# J7AEP_GPU_BXS464_WRAP0_GPU_SS_0_CORE_MMRS register map
Vendor: Texas Instruments
Peripheral module from a debugger description file (folder J721S2).
Registers are 64-bit, access per field, reset 0x0 unless marked. A register's access mark holds for its fields unless they carry their own. Offsets are as the file gives them; lines under a group give offsets from that group; [hi:lo] are bit positions; {n}, {i} and the like mark numbered series; 'fields as' and 'values as' point back to an identical list; <NAME> marks a mode.

## J7AEP_GPU_BXS464_WRAP0_GPU_SS_0_CORE_MMRS (part 1 of 5)
0x608 CORE_MMRS_RGX_CR_PDS_USC_COLLATOR — This register clear the internal resource tracking storage. It must be cleared after reste/power up. A write of '1' to this register clears the PDS Unified Clusters Resource Collator Contents. The PDS USC Resource Collator is a cross-DM controller, meaning this register must not be written during any active TA, 3D or Compute phase. This register must be written during the core initialisation sequence.
  [0] CLEAR wo — Clear PDS Unified Clusters Resource Collator
0x610 CORE_MMRS_RGX_CR_PDS_EXEC_BASE — Base Address in memory where the PDS programs are located
  [39:20] ADDR rw — 1TB addressable, 1 MB aligned base address for PDS programs
0x618 CORE_MMRS_RGX_CR_EVENT_PIXEL_PDS_CODE
  [31:4] ADDR rw — PDS Execution Address for pixel tasks [Positioned as a byte address, 128 bit granularity], 4 GB Range
0x620 CORE_MMRS_RGX_CR_EVENT_PIXEL_PDS_DATA
  fields as CORE_MMRS_RGX_CR_EVENT_PIXEL_PDS_CODE
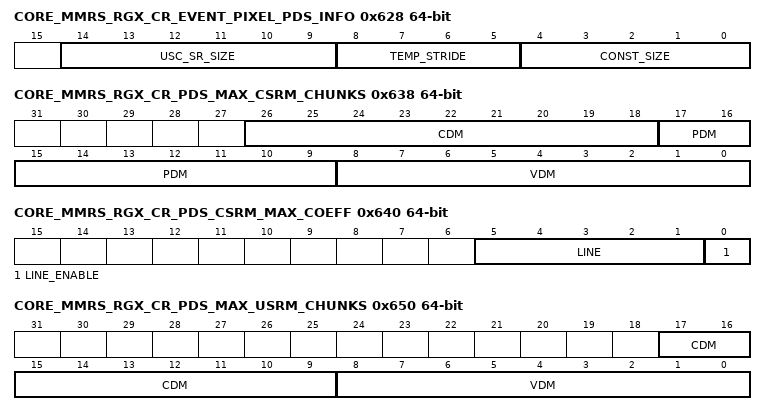
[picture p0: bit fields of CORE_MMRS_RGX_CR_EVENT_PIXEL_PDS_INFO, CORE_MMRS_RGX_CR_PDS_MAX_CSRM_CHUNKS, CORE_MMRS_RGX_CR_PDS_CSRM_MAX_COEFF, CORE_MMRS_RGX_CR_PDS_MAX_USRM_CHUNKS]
0x628 CORE_MMRS_RGX_CR_EVENT_PIXEL_PDS_INFO
  [14:9] USC_SR_SIZE rw — USC Shared Register Data Size in 4x128 bit words [0=0] for pixel event task, if zero pixel event task is skipped
  [8:5] TEMP_STRIDE rw — PDS Temp Size in 128 bit words [0=0] for pixel event tasks
  [4:0] CONST_SIZE rw — PDS Data Size in 128 bit words [0=0] for pixel event tasks, if zero pixel event task is skipped
0x630 CORE_MMRS_RGX_CR_PDS_CSRM — A write of '1' to this register clears the PDS Common Store Resource Manager Contents The PDS CSRM is a cross-DM controller, meaning this register must not be written during any active TA, 3D or Compute phase. This register must be written during the core initialisation sequence.
  [0] CLEAR wo — Clear PDS Common Store Resource Manager, a write to this register results in a one cycle pulse
0x638 CORE_MMRS_RGX_CR_PDS_MAX_CSRM_CHUNKS — Soft Limit Registers for Maximum Allocation Chunks in the Common Store on a Data Master basis. 1024 Allocation Regions exist in the Common Store. Each Allocation Region or Chunk represetns 4x128-bits of space in the Common Store. Setting a Field to 0x0 disables Max Chunk Allocation checking in the Common Store Resource Manager.
  [26:18] CDM rw — Max Number of Allocation Regions to Allocate to the Compute Data Master in Common Store
  [17:9] PDM rw — Max Number of Allocation Regions to Allocate to the Pixel Data Master in Common Store
  [8:0] VDM rw — Max Number of Allocation Regions to Allocate to the VDM Data Master in Common Store
0x640 CORE_MMRS_RGX_CR_PDS_CSRM_MAX_COEFF — The Common Store contains Coefficients and Shared Registers in a maximum of n Lines of 64 Allocation Chunks numbered 0-19, Allocated Dynamically. This Register sets a Soft Limit for the Maximum Line to Allocate for use as a Coefficient Line (0-0xn-1 are valid values)
  [5:1] LINE rw — Coefficients are allocated from Line 0 upwards, this is the maximum Line to use for Coefficients before wrapping
  [0] LINE_ENABLE rw — Enable Max Coefficient Line Limit
0x648 CORE_MMRS_RGX_CR_PDS_USRM — A write of '1' to this register clears the PDS Unified Store Resource Manager Contents. The PDS Unified Store Resource Manager only applies to the vertex and compute data masters. This register must be written during the core initialisation sequence.
  [0] CLEAR wo — Clear PDS Unified Store Resource Manager, a write to this register results in a one cycle pulse
0x650 CORE_MMRS_RGX_CR_PDS_MAX_USRM_CHUNKS — Soft Limit Registers for Maximum Allocation Chunks in the Unified Store on a Data Master basis. 400 Allocation Regions exist in the Unified Store. Each Allocation Region represents 4x128-bits of space in the Unified Store. Setting a Field to 0x0 disables Max Chunk Allocation checking in the Unified Store Resource Manager.
  [17:9] CDM rw — Max Number of Allocation Regions to Allocate to the Compute Data Master in Unified Store
  [8:0] VDM rw — Max Number of Allocation Regions to Allocate to the VDM Data Master in Unified Store
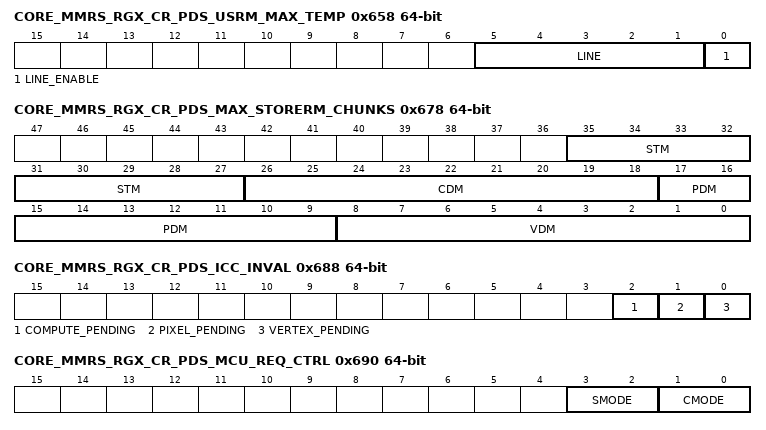
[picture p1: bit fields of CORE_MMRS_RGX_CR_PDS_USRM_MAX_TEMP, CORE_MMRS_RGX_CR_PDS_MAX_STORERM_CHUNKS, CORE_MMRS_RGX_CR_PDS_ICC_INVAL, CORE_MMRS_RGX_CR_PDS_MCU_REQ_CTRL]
0x658 CORE_MMRS_RGX_CR_PDS_USRM_MAX_TEMP — The Unified Store contains Temporaries and Attributes in n Lines of 16 Allocation Chunks numbered 0- n-1, Allocated Dynamically. This Register sets a Soft Limit for the Maximum Line to Allocate for use as a Temporaries Line (0-0xn-1 are valid values) Number of lines n can be calculated by taking the Unified Store Memory Bank Depth and dividing by 16. Hence for a US256 configuration, the USRM manages 16 lines, from 0-15. A smaller US208 configuration manages 13 lines, from 0-12.
  [5:1] LINE rw — Max Line for use as Temporaries
  [0] LINE_ENABLE rw — Enable Max Temporaries Line Limit
0x660 CORE_MMRS_RGX_CR_PDS_UVSRM — A write of '1' to this register clears the PDS Unified Vertex Store Resource Manager Contents The UVS Resource Manager only applies to the vertex data master. This register must be written during the core initialisation sequence.
  [0] CLEAR wo — Clear PDS Unified Vertex Store Resource Manager, a write to this register results in a one cycle pulse
0x670 CORE_MMRS_RGX_CR_PDS_STORERM — A write of '1' to this register clears the PDS Store Resource Manager Contents. The PDS Store Resource Manager is a cross-DM controller, meaning this register must not be written during any active TA, 3D or Compute phase. This register must be written during the core initialisation sequence.
  [0] CLEAR wo — Clear PDS Store Resource Manager, a write to this register results in a one cycle pulse
0x678 CORE_MMRS_RGX_CR_PDS_MAX_STORERM_CHUNKS — Soft Limit Registers for Maximum Allocation Chunks in the PDS Store on a Data Master basis. 488 Allocation Regions exist in the PDS Store. Each Allocation Chunk/Region represents 8x64-bits of space in the PDS Store. Setting a Field to 0x0 disables Max Chunk Allocation checking in the Common Store Resource Manager.
  [35:27] STM rw — Max Number of Allocation Regions to Allocate to the Stream Out Data Master in PDS Store
  [26:18] CDM rw — Max Number of Allocation Regions to Allocate to the Compute Data Master in PDS Store
  [17:9] PDM rw — Max Number of Allocation Regions to Allocate to the Pixel Data Master in PDS Store
  [8:0] VDM rw — Max Number of Allocation Regions to Allocate to the VDM Data Master in PDS Store
0x688 CORE_MMRS_RGX_CR_PDS_ICC_INVAL — A write of '1' any bit to this register clears the PDS Instruction Cache for the selected DM The PDS HW will clear the bits when the operations complete
  [2] COMPUTE_PENDING wo — PDS Instruction Cache Compute [DM 2] has been invalidated
  [1] PIXEL_PENDING wo — PDS Instruction Cache Pixel [DM 1] has been invalidated
  [0] VERTEX_PENDING wo — PDS Instruction Cache Vertex [DM 0] has been invalidated
0x690 CORE_MMRS_RGX_CR_PDS_MCU_REQ_CTRL — The PDS makes requests to the MCU to DMA to the PDS store and write data to memory. This register defines the various cache modes that apply to those requests.
  [3:2] SMODE rw — SLC cache policy to use for requests from the VDM/PDM/CDM/STM resource requestors inside the PDS
  [1:0] CMODE rw — Cache Mode to use for requests from the VDM/PDM/CDM/STM resource requestors inside the PDS
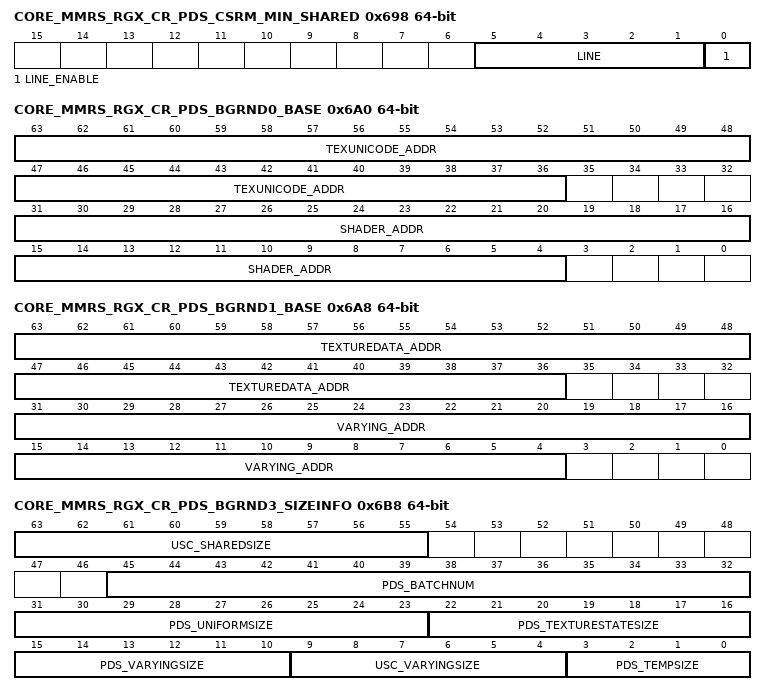
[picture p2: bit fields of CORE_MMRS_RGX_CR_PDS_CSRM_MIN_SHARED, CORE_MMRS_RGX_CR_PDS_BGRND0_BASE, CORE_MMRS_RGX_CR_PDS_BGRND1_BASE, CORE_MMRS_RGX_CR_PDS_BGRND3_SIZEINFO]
0x698 CORE_MMRS_RGX_CR_PDS_CSRM_MIN_SHARED — The Common Store contains Coefficients and Shared Registers in 14 Lines of 64 Allocation Chunks numbered 0-13, Allocated Dynamically. This Register sets a Soft Limit for the Minimum Line to Allocate for use as a Shared Line (0-0xD are valid values)
  [5:1] LINE rw — Shared are allocated from top line downwards, this is the minimum Line to use for Shared Registers before wrapping
  [0] LINE_ENABLE rw — Enable Min Shared Register Line Limit
0x6A0 CORE_MMRS_RGX_CR_PDS_BGRND0_BASE — PDS Background Setup Word 0
  [63:36] TEXUNICODE_ADDR rw — This is the PDS Code Address used for 2 programs. The Program which issues the DMAs [DOUTD etc. ] for uniform data and/or texture state.
  [31:4] SHADER_ADDR rw — The pixel shader base is the base address of the PDS Data Segment. The code segment is address is PDS_PIXEL_SHADERBASE + PDS_PIXELSHADERSIZE. The pixel shader program issues the DOUTU for the Fragment Shader only.
0x6A8 CORE_MMRS_RGX_CR_PDS_BGRND1_BASE — PDS Background Setup Word 1
  [63:36] TEXTUREDATA_ADDR rw — This points to the DMAs to load the Texture State [or contains the State with DOUTW commands]
  [31:4] VARYING_ADDR rw — This is the base address of the PDS Data Segment. The code segment is address is PDS_VARYINGBASE + PDS_VARYINGSIZE [PDS_BGRND_SIZEINFO1].
0x6B0 CORE_MMRS_RGX_CR_PDS_BGRND2_BASE — PDS Background Setup Word 2
  [31:4] UNIFORMDATA_ADDR rw — This points to the DMAs to load the Uniforms [or contains the Uniforms with DOUTW commands]
0x6B8 CORE_MMRS_RGX_CR_PDS_BGRND3_SIZEINFO — If any of the size fields are 0, then that program will not be run. PDS_BGRND_PIXELSHADERSIZE is always 2 128 Bit Words
  [63:55] USC_SHAREDSIZE rw — The common store allocation size for the shared registers [texture and uniform data commbined]
  [45:32] PDS_BATCHNUM rw — The batch ID to be associated with the background
  [31:23] PDS_UNIFORMSIZE rw — The size of the Uniform PDS Data Segment in 128 bit words
  [22:16] PDS_TEXTURESTATESIZE rw — The size of the Texture PDS Data Segment in 128 bit words
  [15:10] PDS_VARYINGSIZE rw — The size of the Varying/Coefficient PDS Data Segment in 128 bit words
  [9:4] USC_VARYINGSIZE rw — The size of the Varying/Coefficient USC Common Store Data in 4x128 bit words
  [3:0] PDS_TEMPSIZE rw — 0 = 0 128 bit words, 1 = 1 128 bit word, this applies to coefficient, uniform and varying state
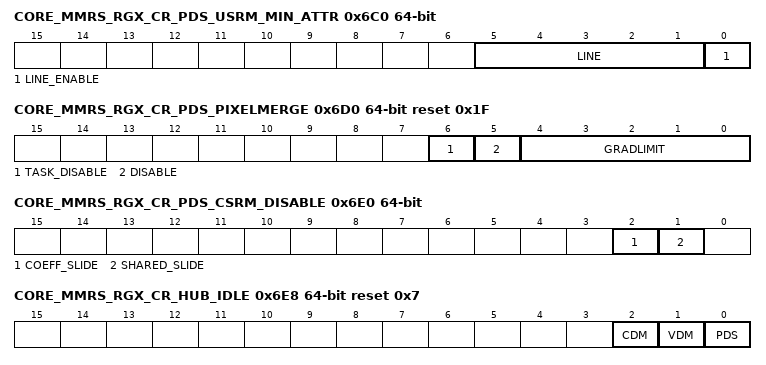
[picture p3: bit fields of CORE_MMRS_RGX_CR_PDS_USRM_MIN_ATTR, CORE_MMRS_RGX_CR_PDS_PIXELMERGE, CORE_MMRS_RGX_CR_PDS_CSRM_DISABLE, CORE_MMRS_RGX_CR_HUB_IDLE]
0x6C0 CORE_MMRS_RGX_CR_PDS_USRM_MIN_ATTR — The Unified Store contains Temporaries and Attributes in n Lines of 16 Allocation Chunks numbered 0 - n-1, Allocated Dynamically. This Register sets a Soft Limit for the Minimum Line to Allocate for use as an Attribute Line (0-0xn-1 are valid values) Number of lines n can be calculated by taking the Unified Store Memory Bank Depth and dividing by 16. Hence for a US256 configuration, the USRM manages 16 lines, from 0-15. A smaller US208 configuration manages 13 lines, from 0-12.
  [5:1] LINE rw — Min Line for use for Attributes
  [0] LINE_ENABLE rw — Enable Min Attributes Line Limit
0x6D0 CORE_MMRS_RGX_CR_PDS_PIXELMERGE reset 0x1F
  [6] TASK_DISABLE rw — Disable pixel merging within a whole pixel fragment task
  [5] DISABLE rw — Disable pixel merging within each 2x2 pixel block of a pixel fragment task
  [4:0] GRADLIMIT rw — Gradient difference limit for PDS PP pixel merging
0x6D8 CORE_MMRS_RGX_CR_PDS_CSRM_USC_DEBUG — When written a non zero value, this register assigns an extra degree of space to be allocated in the Common Store via the PDS CSRM for USC debugging on Shared Allocations. The SIZE field is Allocation Region Granular (i.e 512-bits, or 4x128-bit registers). This register must be set up before the PDS CSRM CLEAR operation.
  [4:0] SIZE rw — Amount of Space [in 512-bit Allocation Regions] to allocate to USC Debug Space on a Shared Allocation.
0x6E0 CORE_MMRS_RGX_CR_PDS_CSRM_DISABLE — When this register is set, the CSRM will be configured on PDS CSRM CLEAR to not reserve any space for Partitions (this is normally governed by the AA MODE and PIXEL OUTPUT CTRL WIDTH register settings), to maximise space in the CSRM for OCL operations. The Shared slide functionality which allows a Shared allocation which fails to slide the allocation window. The Coeff slide functionality allows a Coefficient allocation which fails to slide the allocation window.
  [2] COEFF_SLIDE rw — Disable Slide of Coeff Allocations on Failure
  [1] SHARED_SLIDE rw — Disable Slide of Shared Allocations on Failure
0x6E8 CORE_MMRS_RGX_CR_HUB_IDLE ro reset 0x7
  [2] CDM — CDM Module IDLE
  [1] VDM — VDM Module IDLE
  [0] PDS — PDS Module IDLE
0x6F0 CORE_MMRS_RGX_CR_HUB_PWR ro
  [31:0] NUM_PDS_INST — Number of PDS instructions
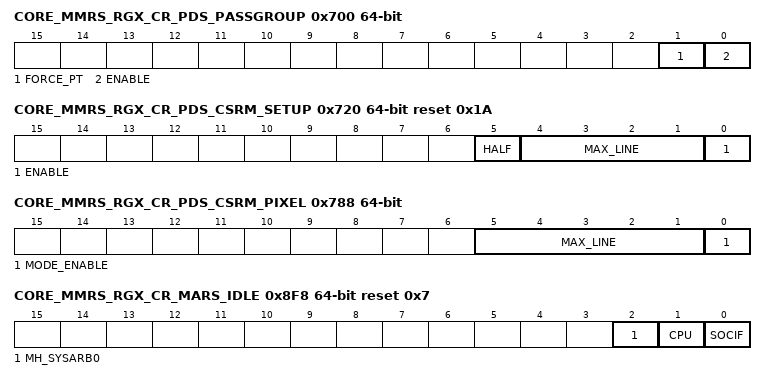
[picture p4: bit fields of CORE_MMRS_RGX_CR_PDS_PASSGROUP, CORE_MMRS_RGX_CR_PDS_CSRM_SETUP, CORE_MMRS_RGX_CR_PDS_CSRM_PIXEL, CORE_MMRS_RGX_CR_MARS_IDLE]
0x700 CORE_MMRS_RGX_CR_PDS_PASSGROUP
  [1] FORCE_PT rw — Force the use of Hard SDs between punchthrough or depth feedback type passes
  [0] ENABLE rw — Enable pass group optimisation within USC by replacing USC Hard SDs with USC Soft SDs for all pass groups in the PDS PP.
0x708 CORE_MMRS_RGX_CR_PDS_COMPUTE_THREAD_BARRIER
  [0] ENABLE rw — Enable thread barrier support in the PDS CDM_RR.
0x720 CORE_MMRS_RGX_CR_PDS_CSRM_SETUP reset 0x1A — If the ENABLE field is set, then when the PDS CSRM is Cleared via the PDS_CSRM_CLEAR register, the value set in the MAX_LINE vector is used to define the maximum Line in the CSRM which is allocatable to Shared Registers/Coefficients. The Space above is reserved for Pixel Partition Data. The CSRM manages space in the USC Common Store using a series of Lines of Allocation Regions. - Allocation Region = 4x128-bit Registers in the USC Common Store - CSRM Line = 64 Allocation Regions = 256x128-bit Registers in teh USC Common Store For CS1088 the maximum allocation size is 13.5 lines = 864 Alloc Regions = 3456 Registers Otherwise, the maximum allocation size is 12.5 lines = 800 Alloc Regions = 3200 Registers For these values the setup would be as follows: - CS1088 - Lines0-13 used, Line 13 is halffull, therefore MAX_LINE = 0xD, HALF = 1 - Non CS1088 - Lines0-12 used, Line 12 is halffull, therefore MAX_LINE = 0xC, HALF = 1
  [5] HALF rw — Top line is prefilled half full
  [4:1] MAX_LINE rw — [Lower 4 bits of] Maximum Line within the CSRM that can be allocated to Shared Registers/Coefficients
  [0] ENABLE rw — Enable use of this register to set the Maximum Line the CSRM can allocate on behalf of the USC Common Store
0x738 CORE_MMRS_RGX_CR_PDS_USRM_DISABLE — When this register is set, the USRM will be configured on PDS USRM CLEAR to disable the Temp/Attribute slide functionality which allows a Temporaries or Attributes allocation which fails to slide the allocation window. The CDM_TEMP_SLIDE bit when set will disable the Temporaries Failure Slide on Compute allocations that fail. The TEMP_FRAGMENTATION bit when set will disable Temporary allocations after window update until the oldest line in the window is empty.
  [0] TEMP_SLIDE rw — Disable Slide of Temp Allocations on Failure
0x788 CORE_MMRS_RGX_CR_PDS_CSRM_PIXEL — The Common Store contains Coefficients and Shared Registers in a maximum of n Lines of 64 Allocation Chunks numbered 0-31, Allocated Dynamically. This Register sets a Soft Limit for the Maximum Line of available Coefficient space, from line 0 upwards (set by PDS_CSRM_MAX_COEFF register) to Allocate for use ONLY by the Pixel Data Master (PDM) only (0-0xn-2 are valid values). Other lines above this limit may also be used for Pixels, but this area is reserved soley for Pixels when enabled.
  [5:1] MAX_LINE rw — Coefficients are allocated from Line 0 upwards, this is the maximum Line to reserve for ONLY PDM Coefficients. The Max line of this region is set in the PDS_CSRM_MAX_COEFF register
  [0] MODE_ENABLE rw — Enable PIXEL RESERVE MODE in the PDS CSRM
0x890 CORE_MMRS_RGX_CR_XPU_BROADCAST reset 0x1 — This register contains a bit for this, the primary XPU and for each secondary device connected to the primary. Bit 0 corresponds to the primary XPU and bits [1 .. GPU_COUNT-1] correspond to the secondary devices. This regsiter is initialised and masked using the GPU_COUNT input such that bits [8 . . GPU_COUNT] always read as '0'. By default, broadcast is enabled for all valid devices.
  [8:0] MASK rw — If bit N is set, forward broadcast XPU register writes to this device.
0x898 CORE_MMRS_RGX_CR_XPU_RW_ORDER reset 0x1
  [0] FORCE rw — 1 - Force reads and writes to complete in order with respect to each other on the XPU register AXI bus by stalling read requests if any writes are outstanding and vice versa. 0 - No ordering is enforced between reads and writes. Writes and reads complete in order with respect to themselves as dictated by AXI ID constraints.
0x8F0 CORE_MMRS_RGX_CR_SLAVE_EVENT ro — This register contains a bit for each slave connected to this, the master XPU. Valid bits are [XPU_MAX_SLAVES-1:0].
  [7:0] STATUS — If bit N is set, an interrupt from slave N is pending.
0x8F8 CORE_MMRS_RGX_CR_MARS_IDLE ro reset 0x7
  [2] MH_SYSARB0 — SYSARB0 Module IDLE
  [1] CPU — CPU Module IDLE
  [0] SOCIF — SOCIF Module IDLE
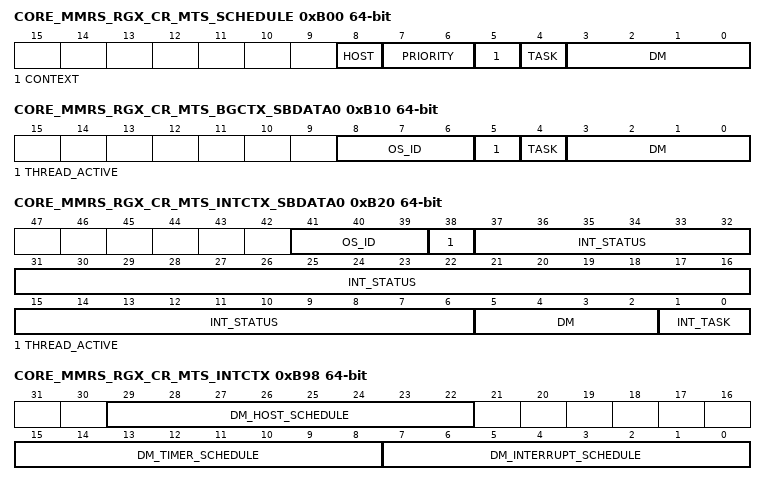
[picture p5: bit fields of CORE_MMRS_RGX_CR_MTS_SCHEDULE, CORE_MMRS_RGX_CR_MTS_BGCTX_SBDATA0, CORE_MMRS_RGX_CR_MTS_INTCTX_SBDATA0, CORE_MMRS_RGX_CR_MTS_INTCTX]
0xB00 CORE_MMRS_RGX_CR_MTS_SCHEDULE — This register allows firmware tasks to be scheduled on the META (Garten) core.
  [8] HOST wo — Host Interrupte kick
  [7:6] PRIORITY wo — DataMaster Priority
  [5] CONTEXT wo
  [4] TASK wo
  [3:0] DM wo — DataMaster Type
0xB08 CORE_MMRS_RGX_CR_MTS_PROC_COMPLETE — This register allows firmware tasks to signal process completion.
  [1] CONTEXT wo
0xB10 CORE_MMRS_RGX_CR_MTS_BGCTX_SBDATA0 ro — This register contains the sideband data for the process running on the background context of thread 0. Reads of this register will be redirected to the correct, thread specific register by hardware.
  [8:6] OS_ID — The OS_ID of the active thread
  [5] THREAD_ACTIVE — Indicates the thread is active
  [4] TASK
  [3:0] DM — DataMaster Type
0xB20 CORE_MMRS_RGX_CR_MTS_INTCTX_SBDATA0 ro — This register contains the sideband data for the process running on the interrupt context of thread 0. Reads of this register will be redirected to the correct, thread specific register by hardware.
  [41:39] OS_ID — The OS_ID of the active thread
  [38] THREAD_ACTIVE — Indicates the thread is active
  [37:6] INT_STATUS — Interrupt Status for 32 event bus lines
  [5:2] DM — DataMaster Type
  [1:0] INT_TASK — Kick Request for timer/BG-request/host
0xB30 CORE_MMRS_RGX_CR_MTS_BGCTX_THREAD0_DM_ASSOC — This register is the DataMaster assocation for the background context of thread 0. Bit <n> high represents DataMaster <n> being permitted to run on the background context of thread 0.
  [15:0] DM_ASSOC rw — DataMaster Association [Active High]
0xB40 CORE_MMRS_RGX_CR_MTS_INTCTX_THREAD0_DM_ASSOC — This register is the DataMaster assocation for the interrupt context of thread 0. Bit <n> high represents DataMaster <n> being permitted to run on the interrupt context of thread 0.
  [15:0] DM_ASSOC rw — DataMaster Association [Active High]
0xB50 CORE_MMRS_RGX_CR_MTS_GARTEN_WRAPPER_CONFIG reset 0x1 — This register contains the configuration options for the Garten wrapper.
  [0] IDLE_CTRL rw
{0xB58+8i} CORE_MMRS_RGX_CR_MTS_DM{i}_INTERRUPT_ENABLE (i=0..5) — Interrupt enable status register for DataMaster {i}
  [31:0] INT_ENABLE rw — Interrupt Enable
0xB88 CORE_MMRS_RGX_CR_MTS_EVENT_MASK — Mask interrupt events
  [31:0] MASK rw — DESCRIPTION
0xB90 CORE_MMRS_RGX_CR_MTS_EVENT_CLEAR — Clear internal interrupt registers
  [31:0] CLEAR wo — DESCRIPTION
0xB98 CORE_MMRS_RGX_CR_MTS_INTCTX ro — This register contains the sideband data for the MTS internal interrupt context registers
  [29:22] DM_HOST_SCHEDULE — A 1 bit counter per DM for host requests
  [15:8] DM_TIMER_SCHEDULE — A 1 bit counter per DM for timer requests
  [7:0] DM_INTERRUPT_SCHEDULE — A 1 bit counter per DM for interrupt requests
0xBA0 CORE_MMRS_RGX_CR_MTS_BGCTX ro — This register contains the sideband data for the MTS internal background context registers
  [7:0] DM_NONCOUNTED_SCHEDULE — A 1 bit counter per DM for non-counted background request
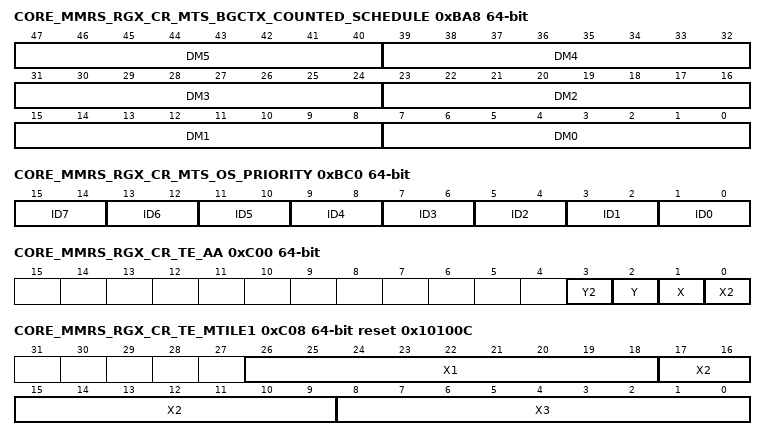
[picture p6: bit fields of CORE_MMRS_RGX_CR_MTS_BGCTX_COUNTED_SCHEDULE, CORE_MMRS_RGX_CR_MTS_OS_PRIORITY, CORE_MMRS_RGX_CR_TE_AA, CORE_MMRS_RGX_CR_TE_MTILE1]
0xBA8 CORE_MMRS_RGX_CR_MTS_BGCTX_COUNTED_SCHEDULE ro — This register contains the sideband data for the MTS internal counted background context counters
  [8n+7:8n] DM{n} (n=0..5) — A 8 bit counter for DM{n}
0xBB0 CORE_MMRS_RGX_CR_MTS_GPU_INT_STATUS ro — This register contains the sideband data for the MTS internal GPU interrupt status
  [31:0] STATUS — A 32 bit register for recored GPU events
0xBC0 CORE_MMRS_RGX_CR_MTS_OS_PRIORITY — Operating System Priority
  [2n+1:2n] ID{n} rw (n=0..7) — Scheduling priority for operating system {n}
0xBC8 CORE_MMRS_RGX_CR_MTS_SCHEDULE_ENABLE reset 0xFF — This register is an active-high mask. When the bit is 0, the MTS_SCHEDULE kick from the corresponding Guest OS is silently discarded. This allows the FW to mask out a Guest OS in order to prevent denial-of-service style attacks.
  [7:0] MASK rw
{0xBD8+0x10000*i} CORE_MMRS_RGX_CR_IRQ_OS{i}_EVENT_STATUS ro (i=0..7) — This register indicates the source of a per-OS host interrupt. This register is set by the firmware and cleared by the host.
  [0] SOURCE
0xBE0 CORE_MMRS_RGX_CR_HOST_IRQ — This register triggers a per-OS host interrupt. The hardware sets the corresponding RGX_CR_IRQ_OS<N>_EVENT_STATUS register.
  [2:0] OSID rw — Indicates the Guest OS for the interrupt
{0xBE8+0x10000*i} CORE_MMRS_RGX_CR_IRQ_OS{i}_EVENT_CLEAR (i=0..7) — This register clears a per-OS host interrupt.
  [0] SOURCE rw
0xBF8 CORE_MMRS_RGX_CR_META_BOOT
  [0] MODE rw — 0 = Don't boot, 1 = Boot
0xC00 CORE_MMRS_RGX_CR_TE_AA — This register controls the anti-aliasing mode of the Tiling Co-Processor, independent control is provided in both X & Y axis. This register needs to be set based on the ISP Samples Per Pixel a core supports. When ISP Samples Per Pixel = 1: 2xmsaa is achieved by enabling Y - TE does AA on Y plane only 4xmsaa is achieved by enabling Y and X - TE does AA on X and Y plane 8xmsaa not supported by XE cores When ISP Samples Per Pixel = 2: 2xmsaa is achieved by enabling X2 - does not affect TE 4xmsaa is achieved by enabling Y and X2 - TE does AA on Y plane only 8xmsaa is achieved by enabling Y, X and X2 - TE does AA on X and Y plane 8xmsaa not supported by XE cores When ISP Samples Per Pixel = 4: 2xmsaa is achieved by enabling X2 - does not affect TE 4xmsaa is achieved by enabling Y2 and X2 - TE does AA on Y plane only 8xmsaa not supported by XE cores
  [3] Y2 rw — Indicates 4xmsaa when X2 and Y2 are set to 1. This does not affect TE and is only used within TPW.
  [2] Y rw — Anti-Aliasing in Y Plane Enabled
  [1] X rw — Anti-Aliasing in X Plane Enabled
  [0] X2 rw — 2x Anti-Aliasing Enabled, affects PPP only
0xC08 CORE_MMRS_RGX_CR_TE_MTILE1 reset 0x10100C — MacroTile Boundaries X Plane
  [26:18] X1 rw — X1 MacroTile boundary, left tile X for second column of macrotiles [16MT mode] - 32 pixels across tile
  [17:9] X2 rw — X2 MacroTile boundary, left tile X for third[16MT] column of macrotiles - 32 pixels across tile
  [8:0] X3 rw — X3 MacroTile boundary, left tile X for fourth column of macrotiles [16MT] - 32 pixels across tile
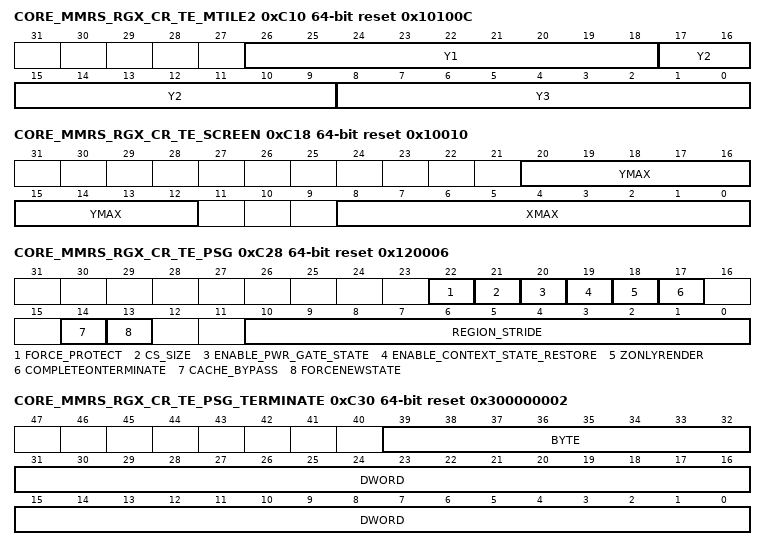
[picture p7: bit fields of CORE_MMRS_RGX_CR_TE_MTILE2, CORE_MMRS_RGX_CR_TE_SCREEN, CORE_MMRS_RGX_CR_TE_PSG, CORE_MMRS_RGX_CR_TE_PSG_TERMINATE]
0xC10 CORE_MMRS_RGX_CR_TE_MTILE2 reset 0x10100C — MacroTile Boundaries Y Plane.
  [26:18] Y1 rw — X1 MacroTile boundary, ltop tile Y for second column of macrotiles [16MT mode] - 32 pixels tile height
  [17:9] Y2 rw — X2 MacroTile boundary, top tile Y for third[16MT] column of macrotiles - 32 pixels tile height
  [8:0] Y3 rw — X3 MacroTile boundary, top tile Y for fourth column of macrotiles [16MT] - 32 pixels tile height
0xC18 CORE_MMRS_RGX_CR_TE_SCREEN reset 0x10010 — In order to perform the tiling operation and generate the display list the maximum screen size must be configured in terms of the number of tiles in X & Y axis.
  [20:12] YMAX rw — Maximum Y tile address visible on screen, 32 pixel tile height, 16Kx16K max screen size
  [8:0] XMAX rw — Maximum X tile address visible on screen, 32 pixel tile width, 16Kx16K max screen size
0xC20 CORE_MMRS_RGX_CR_TE_MTILE — In order to perform the tiling operation and generate the display list the maximum screen size must be configured in terms of the number of tiles in X & Y axis.
  [18:0] STRIDE rw — Number of tiles in a Macrotile. Stride = [XTile * YTiles], tiles 32 pixels across by 32 pixels
0xC28 CORE_MMRS_RGX_CR_TE_PSG reset 0x120006 — This register defines the global control for the Parameter Stream Generator within the Tiling Co-Processor. This module formats the display list generated by the Tiling Co-Processor.
  [22] FORCE_PROTECT rw — When set, the TE shall force the PROTECT bit to 1 for all tiles
  [21] CS_SIZE rw — Size of control stream chunk. 0x0 512 bit 0x1 1024 bit
  [20] ENABLE_PWR_GATE_STATE rw — Enables TE PSG power gate state init. 0x0 Disable 0x1 Enable
  [19] ENABLE_CONTEXT_STATE_RESTORE rw — Enables sampling of Driver TE_STATE_ISP_STATE_ID and TE_ACTIVE_MTILE registers on context switch/restore when set, when reset current local value is preserved.
  [18] ZONLYRENDER rw — Don't invalidate Tail Pointer Cache entries on a Terminate command. Only effective when COMPLETEONTERMINATE is 0x0 0x0 Do Invalidate 0x1 Don't Invalidate
  [17] COMPLETEONTERMINATE rw — 0x1 Write region headers, terminate streams and invalidate tail pointer cache entries on terminate. 0x0 If ZONLYRENDER = 0x0 then force an Interrupt, however if ZONLYRENDER = 0x1 then write region headers and terminate streams.
  [14] CACHE_BYPASS rw — when set, PSG sets its write only cache to bypass mode, effectively disabling the cache
  [13] FORCENEWSTATE rw — Always embed state information in control stream. Debug only.
  [10:0] REGION_STRIDE rw — Number of 4kB Pages devoted to region headers for each Render Target - max needed = 0x500
0xC30 CORE_MMRS_RGX_CR_TE_PSG_TERMINATE reset 0x300000002 — This register can be written by the driver to define what the TA should terminate tile control streams with. Default value is 0x00000002, however this can be replaced with a link pointer to some driver defined control stream.
  [39:32] BYTE rw — Byte to terminate all tile control streams with.
  [31:0] DWORD rw — Double-word to terminate all tile control streams with.
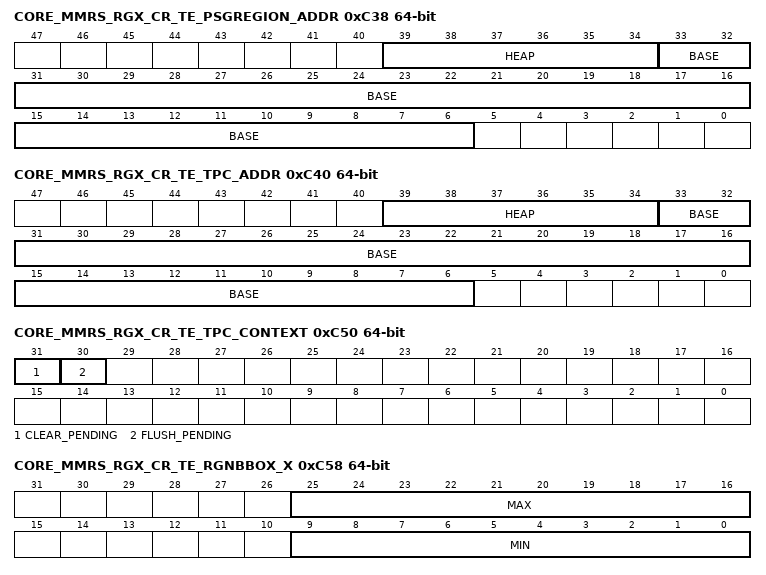
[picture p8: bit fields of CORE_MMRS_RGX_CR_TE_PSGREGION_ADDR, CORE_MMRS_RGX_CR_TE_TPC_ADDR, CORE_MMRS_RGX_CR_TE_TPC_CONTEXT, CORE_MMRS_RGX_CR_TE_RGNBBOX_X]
0xC38 CORE_MMRS_RGX_CR_TE_PSGREGION_ADDR — This register defines the base address in memory of the Region Header writes by the TA. Region headers are the first part of the display list and contain an entry per tile with information on global setup and a link address to parameters.
  [39:34] HEAP rw — 1TB Addressable, 16GB aligned Heap Address for Region Header writes
  [33:6] BASE rw — 16GB Addressable, 512-bit aligned Base Address for Region Header writes
0xC40 CORE_MMRS_RGX_CR_TE_TPC_ADDR — This register defines the base address in memory of the Tail Pointer Cache. A tail pointer is the current last address written to for a tiles individual display list, an entry for active tiles is maintained as primitives are processed by the TA.
  [39:34] HEAP rw — 1TB Addressable, 16GB aligned Heap Address for Tail Pointer Cache.
  [33:6] BASE rw — 16GB Addressable, 512-bit aligned Base Address for Tail Pointer Cache entries. The tail pointer is the current last address written to for a control stream for a tile.
0xC48 CORE_MMRS_RGX_CR_TE_TPC reset 0x8 — This register defines the TPC Memory footprint size per Render Target as a Stride of 4KB pages
  [11:0] STRIDE rw — Number of 4KB pages per Render Target in each TPC footprint - max = 2048
0xC50 CORE_MMRS_RGX_CR_TE_TPC_CONTEXT — The Tail Pointer Cache is used to keep track of the last address written to for a particular tile, this is stored in a mixture of on chip cache and external memory. Under certain circumstances it is neccesary to either reset the cache or flush the on chip cache contents such that they are visible in memory.
  [31] CLEAR_PENDING wo — Reset contents of Tail Pointer Cache
  [30] FLUSH_PENDING wo — Flush contents of Tail Pointer Cache to Memory
0xC58 CORE_MMRS_RGX_CR_TE_RGNBBOX_X ro — Reset or enabled by the PPP_RESETBBOX and PPP_UPDATEBBOX fields in the PPPControl word of the Input Parameter format. This is the maximum extent in X of the post transformed, clipped data before region clipping.
  [25:16] MAX — XMax value for maintained Region Generator Bounding Box, tiles 32 pixels in width
  [9:0] MIN — XMin value for maintained Region Generator Bounding Box, tiles 32 pixels in width
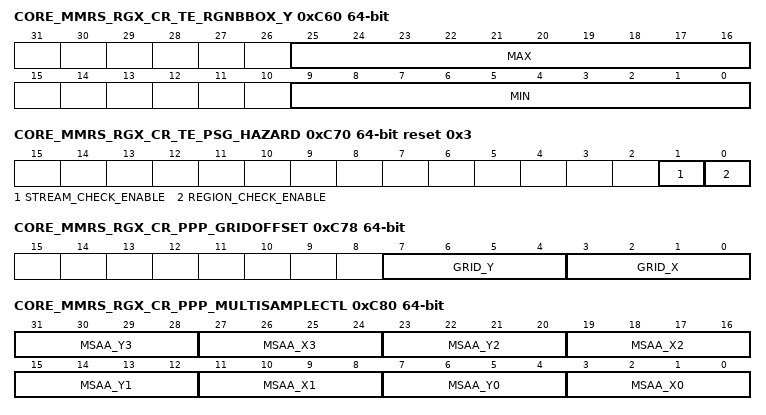
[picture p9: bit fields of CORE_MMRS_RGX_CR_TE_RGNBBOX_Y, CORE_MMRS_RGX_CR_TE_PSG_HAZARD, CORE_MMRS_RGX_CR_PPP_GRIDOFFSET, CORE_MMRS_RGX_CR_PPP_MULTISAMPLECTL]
0xC60 CORE_MMRS_RGX_CR_TE_RGNBBOX_Y ro — Reset or enabled by the PPP_RESETBBOX and PPP_UPDATEBBOX fields in the PPP Control word of the Input Parameter format. This is the maximum extent in Y of the post transformed, clipped data before region clipping.
  [25:16] MAX — YMax value for maintained Region Generator Bounding Box, tiles 16 pixels in height
  [9:0] MIN — YMin value for maintained Region Generator Bounding Box, tiles 16 pixels in height
0xC68 CORE_MMRS_RGX_CR_TE_RGNHDR_INIT — A write of '1' to this register starts the TE Region Header Initialisation Sequence The TE HW will clear the PENDING bit once the operation is complete
  [0] PENDING wo — Start TE Region Header Initialisation
0xC70 CORE_MMRS_RGX_CR_TE_PSG_HAZARD reset 0x3 — Control of hazard checking in SLC for TE PSG requesters
  [1] STREAM_CHECK_ENABLE rw — when set, PSG will enable hazard checking in the SLC for control stream writes
  [0] REGION_CHECK_ENABLE rw — when set, PSG will enable hazard checking in the SLC for region header writes
0xC78 CORE_MMRS_RGX_CR_PPP_GRIDOFFSET — Sample position grid offset for use when MSAA/ODAA is DISABLED DX (0.0,0.0) OpenGL (0.5,0.5) Acts as the 9th multisample position when MSAA is ENABLED.
  [7:4] GRID_Y rw — Unsigned sub-pixel offset
  [3:0] GRID_X rw — Unsigned sub-pixel offset
0xC80 CORE_MMRS_RGX_CR_PPP_MULTISAMPLECTL — Sample position grid offset for use in 2x, 4x, 8xMSAA and ODAA modes.
  [31:28] MSAA_Y3 rw — Unsigned sub-pixel offset for the 4th multisample Y position
  [27:24] MSAA_X3 rw — Unsigned sub-pixel offset for the 4th multisample X position
  [23:20] MSAA_Y2 rw — Unsigned sub-pixel offset for the 3rd multisample Y position
  [19:16] MSAA_X2 rw — Unsigned sub-pixel offset for the 3rd multisample X position
  [15:12] MSAA_Y1 rw — Unsigned sub-pixel offset for the 2nd multisample Y position
  [11:8] MSAA_X1 rw — Unsigned sub-pixel offset for the 2nd multisample X position
  [7:4] MSAA_Y0 rw — Unsigned sub-pixel offset for the 1st multisample Y position
  [3:0] MSAA_X0 rw — Unsigned sub-pixel offset for the 1st multisample X position
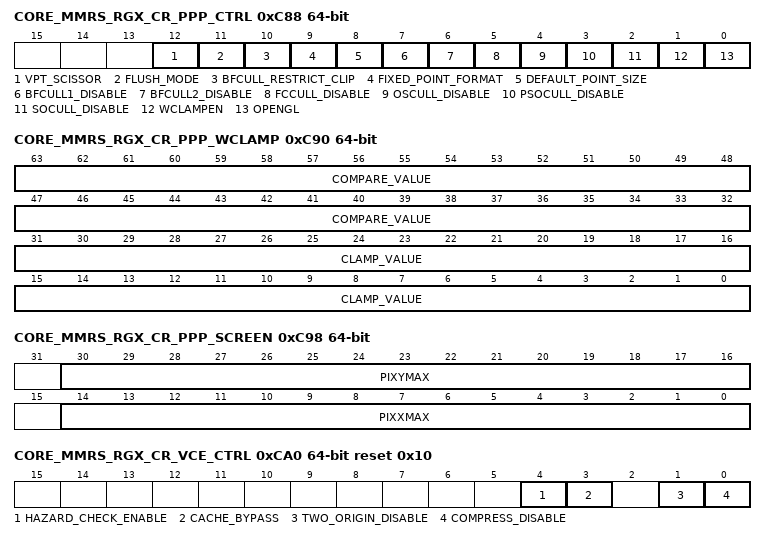
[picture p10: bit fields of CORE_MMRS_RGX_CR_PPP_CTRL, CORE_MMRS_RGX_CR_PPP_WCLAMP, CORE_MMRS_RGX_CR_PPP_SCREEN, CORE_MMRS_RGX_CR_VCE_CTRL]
0xC88 CORE_MMRS_RGX_CR_PPP_CTRL — This register controls the global setup of the PPP.
  [12] VPT_SCISSOR rw — When 0 the PPP will insert state updates on change of VPT ID, When 1 this feature is disabled
  [11] FLUSH_MODE rw — when 0 PPP will supress end of draw call flushed from reaching the Clipper and TA pipeline, This will break batch number funstionality but will give better primitive block utiliastion. when 1 PPP will not supress any flushes
  [10] BFCULL_RESTRICT_CLIP rw — When set, clipped primitives are only back-face culled after the clipper. 0 Enable early back face cull for clipped primitives 1 Disable early cull
  [9] FIXED_POINT_FORMAT rw — When set, the PPP will use a fixed point format of 16. 8 rather than 16.4. 0 16.4 fixed point format 1 16.8 fixed point format
  [8] DEFAULT_POINT_SIZE rw — When set, the PPP will use the default point size rather than reading it from the vertex. 0 Point size read from vertex 1 Default point size of 3F800000 used
  [7] BFCULL1_DISABLE rw — Disable for fully clipped culling 0 First back face cull block enabled 1 First back face cull block disabled
  [6] BFCULL2_DISABLE rw — Disable for fully clipped culling 0 Second back face cull block enabled 1 Second back face cull block disabled
  [5] FCCULL_DISABLE rw — Disable for fully clipped culling 0 Fully clipped culling enabled 1 Fully clipped culling disabled
  [4] OSCULL_DISABLE rw — Disable for off screen culling 0 Off screen culling enabled 1 Off screen culling disabled
  [3] PSOCULL_DISABLE rw — Disable for perfect small object culling 0 Perfect small object culling enabled 1 Perfect small object culling disabled
  [2] SOCULL_DISABLE rw — Disable for small object culling 0 Small object culling enabled 1 Small object culling disabled
  [1] WCLAMPEN rw — Enable W clamping 0 W clamping disabled 1 W clamping enabled
  [0] OPENGL rw — Select OpenGL or D3D mode 0 D3D 1 OpenGL
0xC90 CORE_MMRS_RGX_CR_PPP_WCLAMP rw
  [63:32] COMPARE_VALUE — Compare value for W clamping. See the Input parameter format, viewport transform for details. Compare is applied post viewport transform. Note that this value cannot be negative.
  [31:0] CLAMP_VALUE — Clamp value for W clamping. See the Input parameter format, viewport transform for details. Clamp is applied post viewport transform, if the w value is less than the WCOMPARE value. Note that this value cannot be negative.
0xC98 CORE_MMRS_RGX_CR_PPP_SCREEN — In order to perform the tiling operation and generate the display list the maximum screen size must be configured in terms of the number of pixels in X & Y axis since this may not be the same as the number of tiles defined in the RGX_CR_TE_SCREEN register.
  [30:16] PIXYMAX rw — Screen height in pixels. [16K x 16K max screen size]
  [14:0] PIXXMAX rw — Screen width in pixels.[16K x 16K max screen size]
0xCA0 CORE_MMRS_RGX_CR_VCE_CTRL reset 0x10 — This register controls the global setup of the VCE.
  [4] HAZARD_CHECK_ENABLE rw — when set, hazard checking will be enabled in SLC for parameter buffer writes
  [3] CACHE_BYPASS rw — when set, VCE sets its write only cache to bypass mode, effectively disabling the cache
  [1] TWO_ORIGIN_DISABLE rw — When set, raw mode is selected in place of 2-origin delta stream compression mode
  [0] COMPRESS_DISABLE rw — When set, vertex compression is disabled. I.e., raw mode is forced for all vertices
0xCA8 CORE_MMRS_RGX_CR_TE_CLEAR_LISTS_AFTER_ABORT — A write of '1' to this register tells the TE we are resuming after an Abort and Partial Render Sequence
  [0] PULSE wo — TE Clears all references after Abort and Partial Render Sequence
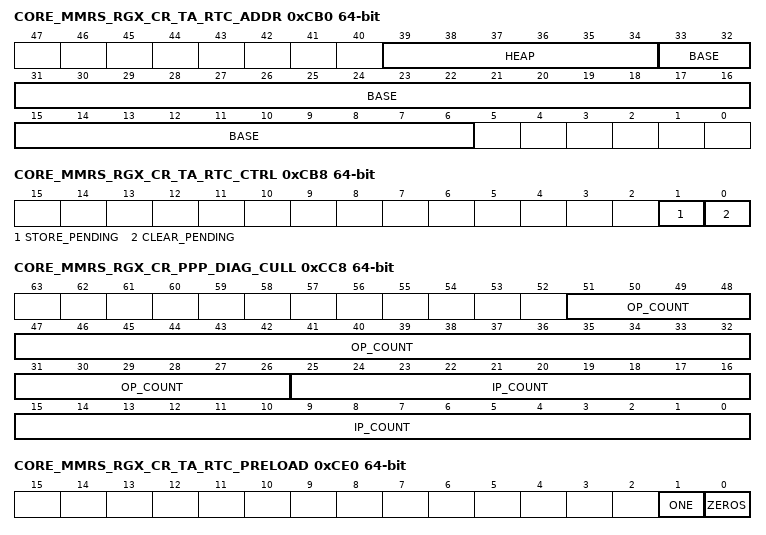
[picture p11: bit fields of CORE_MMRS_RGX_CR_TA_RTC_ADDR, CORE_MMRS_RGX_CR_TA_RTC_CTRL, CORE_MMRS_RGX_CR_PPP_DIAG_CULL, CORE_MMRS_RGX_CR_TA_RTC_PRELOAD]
0xCB0 CORE_MMRS_RGX_CR_TA_RTC_ADDR — This register defines the base address in memory of the TA Render Target Caches, for the VCE, TEAC and PSG
  [39:34] HEAP rw — 1TB Addressable, 16GB aligned Heap Address for TA Render Target Caches
  [33:6] BASE rw — 16GB Addressabreadonly, le, 512-bit aligned Base Address for TA Render Target Caches.
0xCB8 CORE_MMRS_RGX_CR_TA_RTC_CTRL — A write of '1' to Bit 0 of this register Clears the RTC. A write of '1' to Bit 1 of this register Stores the RTC to memory (address specified in TA_RTC_ADDR register)
  [1] STORE_PENDING wo — Store RTC
  [0] CLEAR_PENDING wo — Clear RTC
0xCC0 CORE_MMRS_RGX_CR_TA_CONTEXT_STATE_BASE — The base address in external memory of the TA's context state buffer, to which the PPP will store the state on a context store and from which the VDM will reload on a context resume
  [39:4] ADDR rw — 1TB range, 128-bit aligned base address
0xCC8 CORE_MMRS_RGX_CR_PPP_DIAG_CULL ro — Diagnois register keeps a count of the number of primtives entering the PPP culling module
  [51:26] OP_COUNT — count of primitives exiting the cull block
  [25:0] IP_COUNT — count of primitives entering the cull block
0xCD0 CORE_MMRS_RGX_CR_PPP ro — Checksum generated from the output of the PPP
  [31:0] CHECKSUM — checksum generated from the output of the PPP
0xCD8 CORE_MMRS_RGX_CR_UVS_CLEAR — A write of '1' to this register starts the UVS Clear Operation This register must be written during the core initialisation sequence.
  [0] PENDING wo — Start UVS Clear Operation, a write to this register results in a one cycle pulse
0xCE0 CORE_MMRS_RGX_CR_TA_RTC_PRELOAD — When set, the RTC will be Preloaded with Zeros (or a nonRTA render target of 1) on a Clear Operation (used when Render Targets are not in use to remove the need for memory allocation)
  [1] ONE rw — Preload RTC with Render Target 0 set on a Clear. Used when resuming a TA phase after coarse grain context switch
  [0] ZEROS rw — Preload RTC with Zeros on a Clear
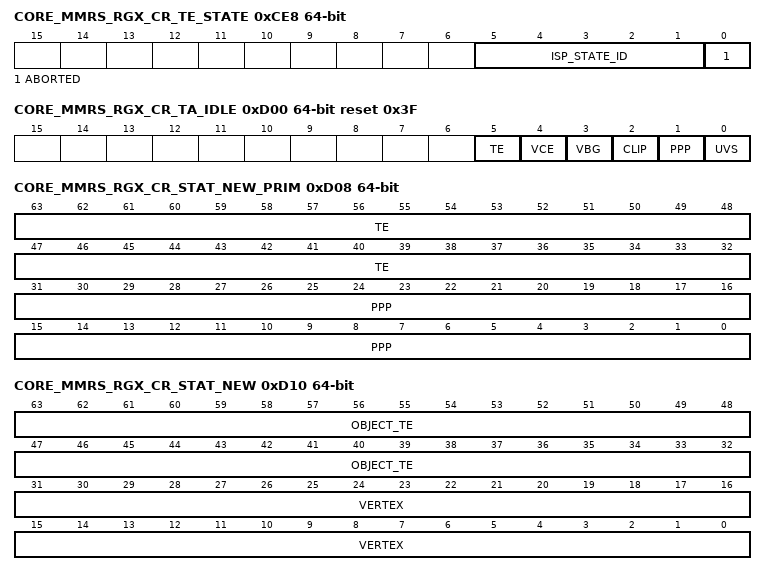
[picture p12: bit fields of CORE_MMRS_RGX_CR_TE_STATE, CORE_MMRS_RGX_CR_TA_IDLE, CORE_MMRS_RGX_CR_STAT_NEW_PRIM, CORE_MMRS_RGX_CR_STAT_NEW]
0xCE8 CORE_MMRS_RGX_CR_TE_STATE ro — This register should be Sampled by the Driver on Context Switch and Restored before the Resume of the TA Context
  [5:1] ISP_STATE_ID
  [0] ABORTED — TA had been aborted in the past
0xCF0 CORE_MMRS_RGX_CR_VCE_HALT — The MicroKernel must halt VCE processing (consumption of it's pages allocated by PM) before we can do a Partial Render in the Rogue Architecture. When it writes this register, the VCE will detect this on a notify pulse and assert the return signal until it has completed processing and fenced memory. The VCE will remain in this state until it notes either a RGX_CR_TE_RESUME_AFTER_ABORT_PULSE or RGX_CR_TE_CLEAR_LISTS_AFTER_ABORT_PULSE where it will resume processing.
  [0] PENDING wo — VCE is Halting after Current Block
0xCF8 CORE_MMRS_RGX_CR_TE_RESUME_AFTER_ABORT — A write of '1' to this register tells the TE we are resuming after an Abort but that no Partial Render took place
  [0] PULSE wo — TE is restarted and reattempts failing allocation after Out Of Memory event only
0xD00 CORE_MMRS_RGX_CR_TA_IDLE ro reset 0x3F
  [5] TE — TE Module IDLE
  [4] VCE — VCE Module IDLE
  [3] VBG — VBG Module IDLE
  [2] CLIP — CLIP Module IDLE
  [1] PPP — PPP Module IDLE
  [0] UVS — UVS Module IDLE
0xD08 CORE_MMRS_RGX_CR_STAT_NEW_PRIM ro
  [63:32] TE — Number of primitives into TE
  [31:0] PPP — Number of primitives into PPP
0xD10 CORE_MMRS_RGX_CR_STAT_NEW ro
  [63:32] OBJECT_TE — Number of Control Stream Updates by TE
  [31:0] VERTEX — Number of vertices
0xD20 CORE_MMRS_RGX_CR_TE_PSG_RTC — This register should be Sampled by the Driver on VDM Context Switch Terminate TA FINISHED event and Restored before the Resume of the TA Context
  [11:0] ACTIVE_RTS rw — RTAs active at the point of the VDM Context SWitch
0xD28 CORE_MMRS_RGX_CR_VCE_CACHE_FLUSH — The MicroKernel can use this to flush the VCE write only cache at the end of TA phase render. When it writes this register, the VCE will detect this on a notify pulse and assert the return signal until it has completed processing and flushed to memory.
  [0] PENDING wo — VCE is Flushing its write only cache to memory
0xD30 CORE_MMRS_RGX_CR_TE_CACHE_FLUSH — The MicroKernel can use this to flush the TE write only cache at the end of TA phase render. When it writes this register, the TE will detect this on a notify pulse and assert the return signal until it has completed processing and flushed to memory.
  [0] PENDING wo — TE is Flushing its write only cache to memory
0xD38 CORE_MMRS_RGX_CR_PM_CACHE_FLUSH — The MicroKernel can use this to flush the PM write only cache at the end of TA phase render. When it writes this register, the PM will detect this on a notify pulse and assert the return signal until it has completed processing and flushed to memory.
  [0] PENDING wo — PM is Flushing its write only cache to memory
0xF00 CORE_MMRS_RGX_CR_ISP_START_RENDER — Writing '1' to this register initiates a 3D render
  [0] PULSE wo
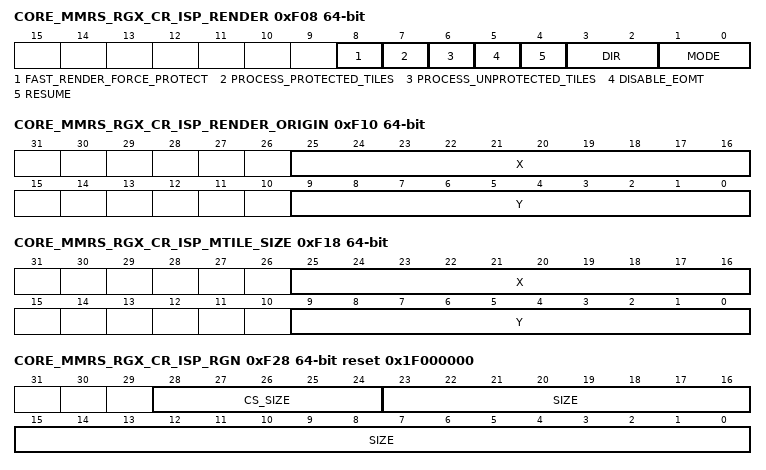
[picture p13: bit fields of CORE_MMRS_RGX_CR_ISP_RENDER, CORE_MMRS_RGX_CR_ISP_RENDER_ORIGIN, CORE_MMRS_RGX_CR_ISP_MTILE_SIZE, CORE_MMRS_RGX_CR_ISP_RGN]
0xF08 CORE_MMRS_RGX_CR_ISP_RENDER — Controls the render
  [8] FAST_RENDER_FORCE_PROTECT rw — When set, all tiles to be rasterised are marked as protected
  [7] PROCESS_PROTECTED_TILES rw — When set, protected tiles are processed
  [6] PROCESS_UNPROTECTED_TILES rw — When set, unprotected tiles are processed
  [5] DISABLE_EOMT rw — Prevent End-of-Macro-Tile flags being sent to ISP
  [4] RESUME rw — Render resume
  [3:2] DIR rw — Render direction
  [1:0] MODE rw — Render type
0xF10 CORE_MMRS_RGX_CR_ISP_RENDER_ORIGIN — This register defines the top-left tile coordinate for the render.
  [25:16] X rw — X coordinate, in tiles
  [9:0] Y rw — Y coordinate, in tiles
0xF18 CORE_MMRS_RGX_CR_ISP_MTILE_SIZE
  [25:16] X rw — Macrotile width, in tiles. A value of zero corresponds to the maximum size
  [9:0] Y rw — Macrotile height, in tiles. A value of zero corresponds to the maximum size
0xF20 CORE_MMRS_RGX_CR_ISP_MTILE_BASE
  [39:2] ADDR rw — 1TB range, 32-bit aligned base address
0xF28 CORE_MMRS_RGX_CR_ISP_RGN reset 0x1F000000 — This register defines the sizes of the allocations of the simple internal parameter data.
  [28:24] CS_SIZE rw — Number of primitive headers in the control stream for a fast 2D render. If the number of primitive headers exceeds the maximum field size or the size of the control stream is unknown, a value of all ones should be written
  [23:0] SIZE rw — Number of Region Headers to fetch
0xF30 CORE_MMRS_RGX_CR_ISP_AA — Controls whether anti-aliasing is enabled or disabled
  [1:0] MODE rw
